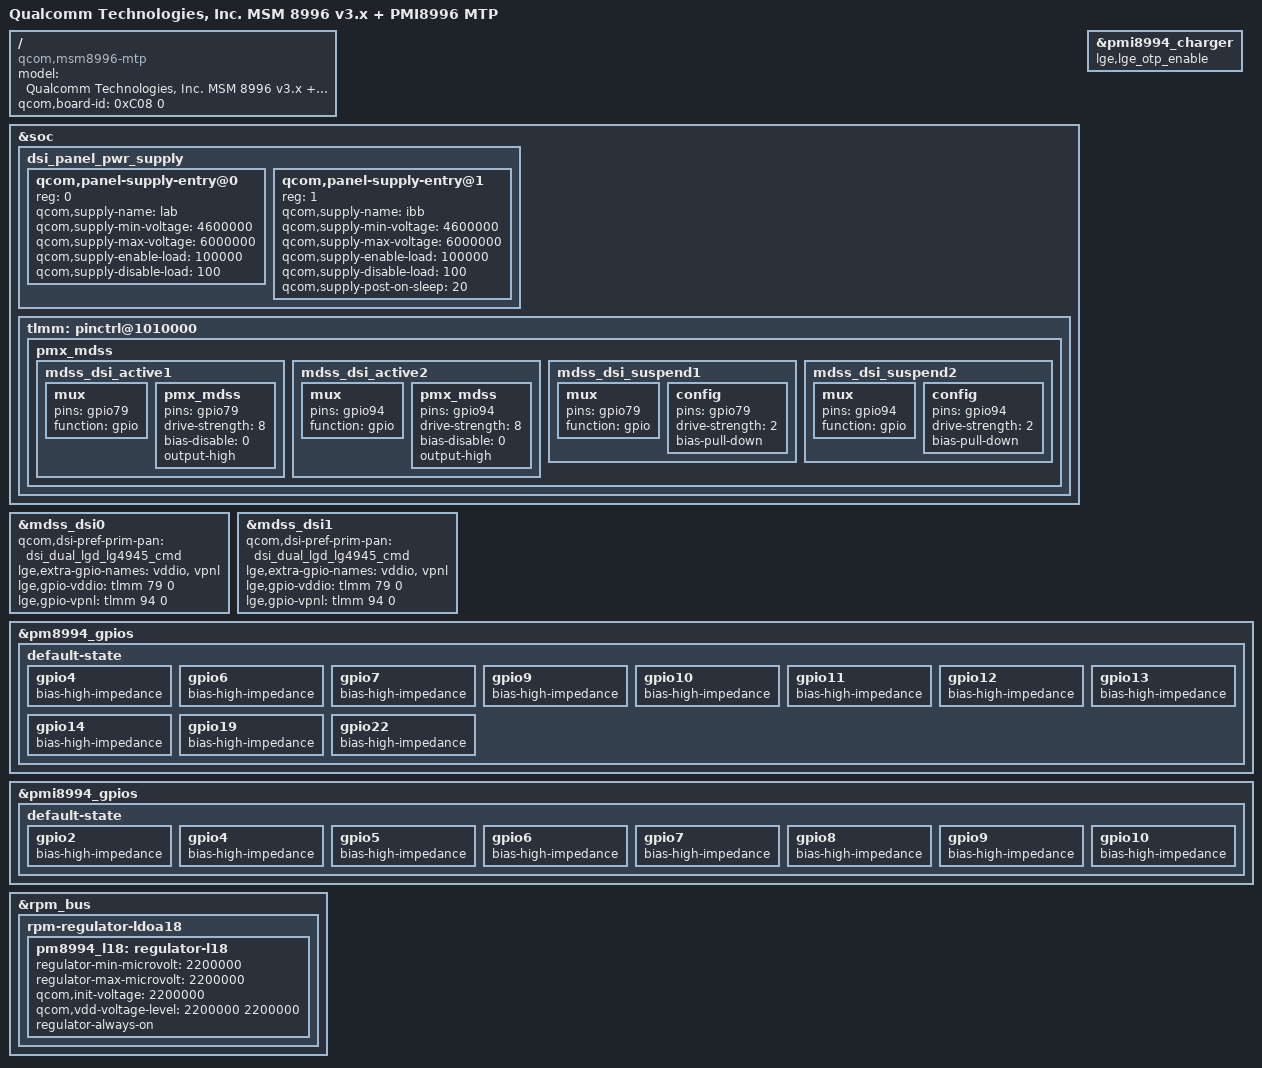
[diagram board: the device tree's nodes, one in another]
/* Copyright (c) 2015, The Linux Foundation. All rights reserved.
 *
 * This program is free software; you can redistribute it and/or modify
 * it under the terms of the GNU General Public License version 2 and
 * only version 2 as published by the Free Software Foundation.
 *
 * This program is distributed in the hope that it will be useful,
 * but WITHOUT ANY WARRANTY; without even the implied warranty of
 * MERCHANTABILITY or FITNESS FOR A PARTICULAR PURPOSE.  See the
 * GNU General Public License for more details.
 */


/dts-v1/;

#include "../../../qcom/msm8996-v3.dtsi"
#include "../../../qcom/msm-pmi8996.dtsi"
#include "../../../qcom/msm8996-mtp.dtsi"
#include "msm8996-h1_global.dtsi"

/ {
	model = "Qualcomm Technologies, Inc. MSM 8996 v3.x + PMI8996 MTP";
	compatible = "qcom,msm8996-mtp", "qcom,msm8996", "qcom,mtp";
	qcom,board-id = <0xC08 0>;
};

/* Display Function */
&soc {
	dsi_panel_pwr_supply: dsi_panel_pwr_supply {
		#address-cells = <1>;
		#size-cells = <0>;

		qcom,panel-supply-entry@0 {
			reg = <0>;
			qcom,supply-name = "lab";
			qcom,supply-min-voltage = <4600000>;
			qcom,supply-max-voltage = <6000000>;
			qcom,supply-enable-load = <100000>;
			qcom,supply-disable-load = <100>;
		};

		qcom,panel-supply-entry@1 {
			reg = <1>;
			qcom,supply-name = "ibb";
			qcom,supply-min-voltage = <4600000>;
			qcom,supply-max-voltage = <6000000>;
			qcom,supply-enable-load = <100000>;
			qcom,supply-disable-load = <100>;
			qcom,supply-post-on-sleep = <20>;
		};
	};
};

&mdss_dsi0 {
	qcom,dsi-pref-prim-pan = <&dsi_dual_lgd_lg4945_cmd>;

	lge,extra-gpio-names = "vddio", "vpnl";

	lge,gpio-vddio = <&tlmm 79 0>;
	lge,gpio-vpnl = <&tlmm 94 0>;
};

&mdss_dsi1 {
	qcom,dsi-pref-prim-pan = <&dsi_dual_lgd_lg4945_cmd>;

	lge,extra-gpio-names = "vddio", "vpnl";

	lge,gpio-vddio = <&tlmm 79 0>;
	lge,gpio-vpnl = <&tlmm 94 0>;
};

/* pinctrl for Display function
 * GPIO79 : LCD_VDD_IO_EN
 * GPIO94 : LCD_VCL_EN
 */
&soc {
	tlmm: pinctrl@1010000 {
		pmx_mdss: pmx_mdss {
			mdss_dsi_active1: mdss_dsi_active1 {
				mux {
					pins = "gpio79";
					function = "gpio";
				};

				pmx_mdss {
					pins = "gpio79";
					drive-strength = <8>; /* 8 mA */
					bias-disable = <0>; /* no pull */
					output-high;
				};
			};
			mdss_dsi_active2: mdss_dsi_active2 {
				mux {
					pins = "gpio94";
					function = "gpio";
				};

				pmx_mdss {
					pins = "gpio94";
					drive-strength = <8>; /* 8 mA */
					bias-disable = <0>; /* no pull */
					output-high;
				};
			};
			mdss_dsi_suspend1: mdss_dsi_suspend1 {
				mux {
					pins = "gpio79";
					function = "gpio";
				};

				config {
					pins = "gpio79";
					drive-strength = <2>; /* 2 mA */
					bias-pull-down; /* pull down */
				};
			};
			mdss_dsi_suspend2: mdss_dsi_suspend2 {
				mux {
					pins = "gpio94";
					function = "gpio";
				};

				config {
					pins = "gpio94";
					drive-strength = <2>; /* 2 mA */
					bias-pull-down; /* pull down */
				};
			};
		};
	};
};

&pmi8994_charger {
    lge,lge_otp_enable;
};

/* set unused gpio to off */
&pm8994_gpios {
	default-state {
	gpio4 {
			bias-high-impedance;
			status = "okay";
		};

	gpio6 {
			bias-high-impedance;
			status = "okay";
		};

	gpio7 {
			bias-high-impedance;
			status = "okay";
		};

	gpio9 {
			bias-high-impedance;
			status = "okay";
		};

	gpio10 {
			bias-high-impedance;
			status = "okay";
		};

	gpio11 {
			bias-high-impedance;
			status = "okay";
		};

	gpio12 {
			bias-high-impedance;
			status = "okay";
		};

	gpio13 {
			bias-high-impedance;
			status = "okay";
		};

	gpio14 {
			bias-high-impedance;
			status = "okay";
		};

	gpio19 {
			bias-high-impedance;
			status = "okay";
		};

	gpio22 {
			bias-high-impedance;
			status = "okay";
		};
	};
};

&pmi8994_gpios {
	default-state {
	gpio2 {
			bias-high-impedance;
			status = "okay";
		};

	gpio4 {
			bias-high-impedance;
			status = "okay";
		};

	gpio5 {
			bias-high-impedance;
			status = "okay";
		};

	gpio6 {
			bias-high-impedance;
			status = "okay";
		};

	gpio7 {
			bias-high-impedance;
			status = "okay";
		};

	gpio8 {
			bias-high-impedance;
			status = "okay";
		};

	gpio9 {
			bias-high-impedance;
			status = "okay";
		};

	gpio10 {
			bias-high-impedance;
			status = "okay";
		};
	};
};

&rpm_bus {
	rpm-regulator-ldoa18 {
		status = "okay";
		pm8994_l18: regulator-l18 {
			regulator-min-microvolt = <2200000>;
			regulator-max-microvolt = <2200000>;
			qcom,init-voltage       = <2200000>;
			qcom,vdd-voltage-level = <2200000 2200000>;
			regulator-always-on;
			status = "okay";
		};
	};
};
